AUTOSAR XML (schema 4-0-3)
package /AUTOSAR_Dcm/ImplementationDataTypes
  65 x impl type:
    Dcm_CertAuthorizationInfoType: category=ARRAY
      element authorization: array-size=4, array-size-semantics=FIXED-SIZE, implementation-data-type=uint8
    DataArrayType_WDBI_Factory_SerialNumber_0x12A3: category=ARRAY
      element DataArrayType: array-size=15, array-size-semantics=FIXED-SIZE, implementation-data-type=uint8
    Dcm_OpStatusType: category=VALUE, base-type=uint8, compu {0x00=DCM_INITIAL, 0x01=DCM_PENDING, 0x02=DCM_CANCEL, 0x03=DCM_FORCE_RCRRP_OK}, range raw 0x00..0x03
    RequestDataArray: category=ARRAY
      element RequestDataArray: array-size=255, array-size-semantics=FIXED-SIZE, implementation-data-type=uint8
    DataArrayType_ECUSupplierCodeDataIdentifier_0xF1A1: category=ARRAY
      element DataArrayType: array-size=4, array-size-semantics=FIXED-SIZE, implementation-data-type=uint8
    StartDataOutType_RID_B19Ch_HSMConfigurationLockEnable_B19Ch_StartRoutineOutSignal_ErrorCode: category=VALUE, base-type=uint16, range raw 0..65535
    DataArrayType_VehicleManufacturerECUHardwareNumberDataIdentifier_0xF191: category=ARRAY
      element DataArrayType: array-size=4, array-size-semantics=FIXED-SIZE, implementation-data-type=uint8
    DataArrayType_SystemName_0xF197: category=ARRAY
      element DataArrayType: array-size=4, array-size-semantics=FIXED-SIZE, implementation-data-type=uint8
    DataArrayType_ECUSoftwareInternalVersion_0xF189: category=ARRAY
      element DataArrayType: array-size=7, array-size-semantics=FIXED-SIZE, implementation-data-type=uint8
    SeedArrayType_L1: category=ARRAY
      element SeedArrayType: array-size=4, array-size-semantics=FIXED-SIZE, implementation-data-type=uint8
    Dcm_ConfirmationStatusType: category=VALUE, base-type=uint8, compu {0x00=DCM_RES_POS_OK, 0x01=DCM_RES_POS_NOT_OK, 0x02=DCM_RES_NEG_OK, 0x03=DCM_RES_NEG_NOT_OK}, range raw 0x00..0x03
    StartDataOutType_RID_0300h_OTAReady_Out_RoutineStatus: category=VALUE, base-type=uint8, range raw 0..255
    KeyArrayType_L9: category=ARRAY
      element KeyArrayType: array-size=8, array-size-semantics=FIXED-SIZE, implementation-data-type=uint8
    DataArrayType_ECUSoftwareUNIT1VersionDataIdentifier_0xF1B1: category=ARRAY
      element DataArrayType: array-size=4, array-size-semantics=FIXED-SIZE, implementation-data-type=uint8
    DataArrayType_SystemSupplierECUHardwareVersionNumberDataIdentifier_0xF193: category=ARRAY
      element DataArrayType: array-size=4, array-size-semantics=FIXED-SIZE, implementation-data-type=uint8
    DataArrayType_WDBI_ManufacturingDate_0x12A4: category=ARRAY
      element DataArrayType: array-size=4, array-size-semantics=FIXED-SIZE, implementation-data-type=uint8
    StartDataOutType_RID_B19Ch_HSMConfigurationLockEnable_B19Ch_StartRoutineOutSignal_State: category=VALUE, base-type=uint8, range raw 0..255
    StartDataOutType_RID_B199h_HSMSecureBootEnable_B199h_StartRoutineOutSignal_ErrorCode: category=VALUE, base-type=uint16, range raw 0..65535
    DataArrayType_InputOutputRecordLocalIdentifier_0xBE02: category=ARRAY
      element DataArrayType: array-size=14, array-size-semantics=FIXED-SIZE, implementation-data-type=uint8
    Dcm_ProgConditionsType: category=STRUCTURE
      8 x element, all with category=TYPE_REFERENCE:
        TesterSourceAddr: implementation-data-type=uint16
        ProtocolId: implementation-data-type=uint8
        Sid: implementation-data-type=uint8
        SubFncId: implementation-data-type=uint8
        ReprogramingRequest: implementation-data-type=boolean
        ApplUpdated: implementation-data-type=boolean
        ResponseRequired: implementation-data-type=boolean
        SecLvInfo: implementation-data-type=uint8
    Dcm_CertExpirationDateInfoType: category=ARRAY
      element expirationDate: array-size=3, array-size-semantics=FIXED-SIZE, implementation-data-type=uint8
    Dcm_PresentDateType: category=VALUE, base-type=uint8, range raw 0..255
    DataArrayType_InputOutputRecordLocalIdentifier_0xBE03: category=ARRAY
      element DataArrayType: array-size=6, array-size-semantics=FIXED-SIZE, implementation-data-type=uint8
    Dcm_StatusType: category=VALUE, base-type=uint8, compu {0x00=DCM_E_OK, 0x08=DCM_E_REQUEST_NOT_ACCEPTED, 0x05=DCM_E_PROTOCOL_NOT_ALLOWED, 0x06=DCM_E_ROE_NOT_ACCEPTED, 0x07=DCM_E_PERIODICID_NOT_ACCEPTED, 0x11=DCM_E_COMPARE_KEY_FAILED}, range raw 0x00..0x11
    StartDataOutType_RID_B19Ch_HSMConfigurationLockEnable_B19Ch_StartRoutineOutSignal_ReturnType: category=VALUE, base-type=uint8, range raw 0..255
    StartDataOutType_RID_B19Bh_HSMSecureDebugEnable_B19Bh_StartRoutineOutSignal_ErrorCode: category=VALUE, base-type=uint16, range raw 0..65535
    DataArrayType_PlatformHardwareVersion_0xF17D: category=ARRAY
      element DataArrayType: array-size=11, array-size-semantics=FIXED-SIZE, implementation-data-type=uint8
    Dcm_MsgItemType: category=VALUE, base-type=uint8, range raw 0..255
    Dcm_IdContextType: category=VALUE, base-type=uint8, range raw 0..255
    StartFlexibleInArrayDataType_RID_B19Eh_HSMResponseData_B19Eh_StartRoutineInSignal_Data: category=ARRAY
      element StartFlexibleInArrayDataType: array-size=16, array-size-semantics=FIXED-SIZE, implementation-data-type=uint8
    DataArrayType_ECUSerialNumberDataIdentifier_0xF18C: category=ARRAY
      element DataArrayType: array-size=15, array-size-semantics=FIXED-SIZE, implementation-data-type=uint8
    DcmDspDidRangeArrayType_DIDs_0100h_0110h: category=ARRAY
      element DcmDspDidRangeArrayType: array-size=30, array-size-semantics=FIXED-SIZE, implementation-data-type=uint8
    DataArrayType_ECUSoftwareUNITnumberDataIdentifier_0xF1B0: category=ARRAY
      element DataArrayType: array-size=1, array-size-semantics=FIXED-SIZE, implementation-data-type=uint8
    DataArrayType_ECUSoftwareUnit1IVDDataIdentifier_0xF1C1: category=ARRAY
      element DataArrayType: array-size=32, array-size-semantics=FIXED-SIZE, implementation-data-type=uint8
    DataArrayType_CANDataBaseVersionNumberDataIdentifier_0xF100: category=ARRAY
      element DataArrayType: array-size=4, array-size-semantics=FIXED-SIZE, implementation-data-type=uint8
    Dcm_CertInfoType: category=STRUCTURE
      element authorization: implementation-data-type=Dcm_CertAuthorizationInfoType
      element expirationDate: implementation-data-type=Dcm_CertExpirationDateInfoType
    Dcm_ReturnReadMemoryType: category=VALUE, base-type=uint8, compu {0x02=DCM_READ_FAILED, 0x03=DCM_READ_FORCE_RCRRP, 0x00=DCM_READ_OK, 0x01=DCM_READ_PENDING}, range raw 0x00..0x03
    StartFlexibleOutArrayDataType_RID_B19Dh_HSMChallengeRequest_B19Dh_StartRoutineOutSignal_Data: category=ARRAY
      element StartFlexibleOutArrayDataType: array-size=16, array-size-semantics=FIXED-SIZE, implementation-data-type=uint8
    DTRStatusType: category=VALUE, base-type=uint8, range raw 0..255
    Dcm_MsgLenType: category=VALUE, base-type=uint32, range raw 0..4294967295
    StartDataOutType_RID_B19Bh_HSMSecureDebugEnable_B19Bh_StartRoutineOutSignal_State: category=VALUE, base-type=uint8, range raw 0..255
    SeedArrayType_L9: category=ARRAY
      element SeedArrayType: array-size=8, array-size-semantics=FIXED-SIZE, implementation-data-type=uint8
    DataArrayType_PlatformVersion_0xF17F: category=ARRAY
      element DataArrayType: array-size=11, array-size-semantics=FIXED-SIZE, implementation-data-type=uint8
    KeyArrayType_L1: category=ARRAY
      element KeyArrayType: array-size=4, array-size-semantics=FIXED-SIZE, implementation-data-type=uint8
    StartFlexibleOutArrayDataType_RID_B194h_HSMConfigLockSecureDebug_B194h_StartRoutineOutSignal: category=ARRAY
      element StartFlexibleOutArrayDataType: array-size=2, array-size-semantics=FIXED-SIZE, implementation-data-type=uint8
    Dcm_SesCtrlType: category=VALUE, base-type=uint8, compu {0x01=DCM_DEFAULT_SESSION, 0x02=DCM_PROGRAMMING_SESSION, 0x03=DCM_EXTENDED_DIAGNOSTIC_SESSION, 0x04=DCM_SAFETY_SYSTEM_DIAGNOSTIC_SESSION, 0x10=DCM_EXTENDED_DIAGNOSTIC_MODE_10H, 0x05=DCM_ECU_PROGRAMMING_MODE_05H, 0x50=DCM_QUIESCENT_CURRENT_DIAGNOSTIC_MODE_START, 0x51=DCM_SLEEP_MODE_START_REQUEST, 0xFF=DCM_ALL_SESSION_LEVEL}, range raw 0x01..0xFF
    DataArrayType_ReadECUIdentificationLocalRXSWINDataIdentifier_0xF1EF: category=ARRAY
      element DataArrayType: array-size=40, array-size-semantics=FIXED-SIZE, implementation-data-type=uint8
    Dcm_ReturnWriteMemoryType: category=VALUE, base-type=uint8, compu {0x02=DCM_WRITE_FAILED, 0x03=DCM_WRITE_FORCE_RCRRP, 0x00=DCM_WRITE_OK, 0x01=DCM_WRITE_PENDING}, range raw 0x00..0x03
    Dcm_ProtocolType:
      category=VALUE
      base-type=uint8
      compu {0x00=DCM_OBD_ON_CAN, 0x01=DCM_OBD_ON_FLEXRAY, 0x02=DCM_OBD_ON_IP, 0x03=DCM_UDS_ON_CAN, 0x04=DCM_UDS_ON_FLEXRAY, 0x05=DCM_UDS_ON_IP, 0x06=DCM_ROE_ON_CAN, 0x07=DCM_ROE_ON_FLEXRAY, 0x08=DCM_ROE_ON_IP, 0x09=DCM_PERIODICTRANS_ON_CAN, 0x0A=DCM_PERIODICTRANS_ON_FLEXRAY, 0x0B=DCM_PERIODICTRANS_ON_IP, 0x0C=DCM_NO_ACTIVE_PROTOCOL, 0xF0=DCM_SUPPLIER_1, 0xF1=DCM_SUPPLIER_2, 0xF2=DCM_SUPPLIER_3, 0xF3=DCM_SUPPLIER_4, 0xF4=DCM_SUPPLIER_5, 0xF5=DCM_SUPPLIER_6, 0xF6=DCM_SUPPLIER_7, 0xF7=DCM_SUPPLIER_8, 0xF8=DCM_SUPPLIER_9, 0xF9=DCM_SUPPLIER_10, 0xFA=DCM_SUPPLIER_11, 0xFB=DCM_SUPPLIER_12, 0xFC=DCM_SUPPLIER_13, 0xFD=DCM_SUPPLIER_14, 0xFE=DCM_SUPPLIER_15}
      range raw 0x00..0xFE
    StartDataOutType_RID_B19Bh_HSMSecureDebugEnable_B19Bh_StartRoutineOutSignal_ReturnType: category=VALUE, base-type=uint8, range raw 0..255
    Dcm_RoeStateType: category=VALUE, base-type=uint8, compu {0x00=DCM_ROE_ACTIVE, 0x01=DCM_ROE_UNACTIVE}, range raw 0x00..0x01
    DataArrayType_VehicleManufacturerSparePartNumberDataIdentifier_0xF187: category=ARRAY
      element DataArrayType: array-size=10, array-size-semantics=FIXED-SIZE, implementation-data-type=uint8
    DataArrayType_NonSleepCollectedEachEcuDataIdentifier_0xED90: category=ARRAY
      element DataArrayType: array-size=15, array-size-semantics=FIXED-SIZE, implementation-data-type=uint8
    StartDataOutType_RID_B199h_HSMSecureBootEnable_B199h_StartRoutineOutSignal_ReturnType: category=VALUE, base-type=uint8, range raw 0..255
    DataArrayType_ECUManufacturingDateDataIdentifier_0xF18B: category=ARRAY
      element DataArrayType: array-size=4, array-size-semantics=FIXED-SIZE, implementation-data-type=uint8
    DataArrayType_UserOptionRecordLocalIdentifier_0xBE01: category=ARRAY
      element DataArrayType: array-size=8, array-size-semantics=FIXED-SIZE, implementation-data-type=uint8
    StartDataOutType_RID_B19Ah_HSMFTDDisable_B19Ah_StartRoutineOutSignal_ErrorCode: category=VALUE, base-type=uint16, range raw 0..65535
    StartDataOutType_RID_B19Ah_HSMFTDDisable_B19Ah_StartRoutineOutSignal_ReturnType: category=VALUE, base-type=uint8, range raw 0..255
    Dcm_SecLevelType: category=VALUE, base-type=uint8, compu {0x00=DCM_SEC_LEV_LOCKED, 0x01=DCM_SEC_LEV_L1, 0x09=DCM_SEC_LEV_L9, 0x21=DCM_SEC_LEV_L21, 0xFF=DCM_SEC_LEV_ALL}, range raw 0x00..0xFF
    Dcm_NegativeResponseCodeType:
      category=VALUE
      base-type=uint8
      compu {0x00=DCM_E_POSITIVERESPONSE, 0x10=DCM_E_GENERALREJECT, 0x11=DCM_E_SERVICENOTSUPPORTED, 0x12=DCM_E_SUBFUNCTIONNOTSUPPORTED, 0x13=DCM_E_INCORRECTMESSAGELENGTHORINVALIDFORMAT, 0x14=DCM_E_RESPONSETOOLONG, 0x21=DCM_E_BUSYREPEATREQUEST, 0x22=DCM_E_CONDITIONSNOTCORRECT, 0x24=DCM_E_REQUESTSEQUENCEERROR, 0x25=DCM_E_NORESPONSEFROMSUBNETCOMPONENT, 0x26=DCM_E_FAILUREPREVENTSEXECUTIONOFREQUESTEDACTION, 0x31=DCM_E_REQUESTOUTOFRANGE, 0x33=DCM_E_SECURITYACCESSDENIED, 0x35=DCM_E_INVALIDKEY, 0x36=DCM_E_EXCEEDNUMBEROFATTEMPTS, 0x37=DCM_E_REQUIREDTIMEDELAYNOTEXPIRED, 0x70=DCM_E_UPLOADDOWNLOADNOTACCEPTED, 0x71=DCM_E_TRANSFERDATASUSPENDED, 0x72=DCM_E_GENERALPROGRAMMINGFAILURE, 0x73=DCM_E_WRONGBLOCKSEQUENCECOUNTER, 0x7E=DCM_E_SUBFUNCTIONNOTSUPPORTEDINACTIVESESSION, 0x7F=DCM_E_SERVICENOTSUPPORTEDINACTIVESESSION, 0x81=DCM_E_RPMTOOHIGH, 0x82=DCM_E_RPMTOOLOW, 0x83=DCM_E_ENGINEISRUNNING, 0x84=DCM_E_ENGINEISNOTRUNNING, 0x85=DCM_E_ENGINERUNTIMETOOLOW, 0x86=DCM_E_TEMPERATURETOOHIGH, 0x87=DCM_E_TEMPERATURETOOLOW, 0x88=DCM_E_VEHICLESPEEDTOOHIGH, 0x89=DCM_E_VEHICLESPEEDTOOLOW, 0x8A=DCM_E_THROTTLE_PEDALTOOHIGH, 0x8B=DCM_E_THROTTLE_PEDALTOOLOW, 0x8C=DCM_E_TRANSMISSIONRANGENOTINNEUTRAL, 0x8D=DCM_E_TRANSMISSIONRANGENOTINGEAR, 0x8F=DCM_E_BRAKESWITCH_NOTCLOSED, 0x90=DCM_E_SHIFTERLEVERNOTINPARK, 0x91=DCM_E_TORQUECONVERTERCLUTCHLOCKED, 0x92=DCM_E_VOLTAGETOOHIGH, 0x93=DCM_E_VOLTAGETOOLOW, 0xF0=DCM_E_CRLINTEGRITYCHECKFAILED, 0xF1=DCM_E_CRLEXPIRED, 0xF2=DCM_E_CERTVERIFICATIONFAILED, 0xF3=DCM_E_VMSCNC_3, 0xF4=DCM_E_VMSCNC_4, 0xF5=DCM_E_VMSCNC_5, 0xF6=DCM_E_VMSCNC_6, 0xF7=DCM_E_VMSCNC_7, 0xF8=DCM_E_VMSCNC_8, 0xF9=DCM_E_VMSCNC_9, 0xFA=DCM_E_VMSCNC_A, 0xFB=DCM_E_VMSCNC_B, 0xFC=DCM_E_VMSCNC_C, 0xFD=DCM_E_VMSCNC_D, 0xFE=DCM_E_VMSCNC_E}
      range raw 0x00..0xFF
    Dcm_CommunicationModeType:
      category=VALUE
      base-type=uint8
      compu {0x00=DCM_ENABLE_RX_TX_NORM, 0x01=DCM_ENABLE_RX_DISABLE_TX_NORM, 0x02=DCM_DISABLE_RX_ENABLE_TX_NORM, 0x03=DCM_DISABLE_RX_TX_NORMAL, 0x04=DCM_ENABLE_RX_TX_NM, 0x05=DCM_ENABLE_RX_DISABLE_TX_NM, 0x06=DCM_DISABLE_RX_ENABLE_TX_NM, 0x07=DCM_DISABLE_RX_TX_NM, 0x08=DCM_ENABLE_RX_TX_NORM_NM, 0x09=DCM_ENABLE_RX_DISABLE_TX_NORM_NM, 0x0A=DCM_DISABLE_RX_ENABLE_TX_NORM_NM, 0x0B=DCM_DISABLE_RX_TX_NORM_NM, 0x03=DCM_DISABLE_RX_TX_NORM}
      range raw 0x00..0x0B
    StartDataOutType_RID_B199h_HSMSecureBootEnable_B199h_StartRoutineOutSignal_State: category=VALUE, base-type=uint8, range raw 0..255
    DataArrayType_ChargingECUSoftwareVersionMobase_0xF101: category=ARRAY
      element DataArrayType: array-size=6, array-size-semantics=FIXED-SIZE, implementation-data-type=uint8
    StartDataOutType_RID_B19Ah_HSMFTDDisable_B19Ah_StartRoutineOutSignal_State: category=VALUE, base-type=uint8, range raw 0..255
    Dcm_EcuStartModeType: category=VALUE, base-type=uint8, compu {0x00=DCM_COLD_START, 0x01=DCM_WARM_START}, range raw 0x00..0x01
package /AUTOSAR_Dcm/ClientServerInterfaces
  37 x client server interface, all with is-service=true:
    RoutineServices_RID_B19Bh_HSMSecureDebugEnable
      operation Start: possible-error=[RoutineServices_RID_B19Bh_HSMSecureDebugEnable/DCM_E_FORCE_RCRRP, RoutineServices_RID_B19Bh_HSMSecureDebugEnable/DCM_E_PENDING, RoutineServices_RID_B19Bh_HSMSecureDebugEnable/E_NOT_OK]
        6 x arg:
          OpStatus: type=Dcm_OpStatusType, direction=IN
          DataOut_B19Bh_StartRoutineOutSignal_ReturnType: type=StartDataOutType_RID_B19Bh_HSMSecureDebugEnable_B19Bh_StartRoutineOutSignal_ReturnType, direction=OUT
          DataOut_B19Bh_StartRoutineOutSignal_State: type=StartDataOutType_RID_B19Bh_HSMSecureDebugEnable_B19Bh_StartRoutineOutSignal_State, direction=OUT
          DataOut_B19Bh_StartRoutineOutSignal_ErrorCode: type=StartDataOutType_RID_B19Bh_HSMSecureDebugEnable_B19Bh_StartRoutineOutSignal_ErrorCode, direction=OUT
          currentDataLength: type=uint16, direction=INOUT
          ErrorCode: type=Dcm_NegativeResponseCodeType, direction=OUT
      error DCM_E_FORCE_RCRRP: error-code=12
      error DCM_E_PENDING: error-code=10
      error E_NOT_OK: error-code=1
    DataServices_VehicleManufacturerSparePartNumberDataIdentifier_0xF187
      operation ReadData: possible-error=DataServices_VehicleManufacturerSparePartNumberDataIdentifier_0xF187/E_NOT_OK
        arg Data: type=DataArrayType_VehicleManufacturerSparePartNumberDataIdentifier_0xF187, direction=OUT
      operation ConditionCheckRead: possible-error=DataServices_VehicleManufacturerSparePartNumberDataIdentifier_0xF187/E_NOT_OK
        arg ErrorCode: type=Dcm_NegativeResponseCodeType, direction=OUT
      error E_NOT_OK: error-code=1
      error DCM_E_PENDING: error-code=10
    DataServices_CANDataBaseVersionNumberDataIdentifier_0xF100
      operation ReadData: possible-error=DataServices_CANDataBaseVersionNumberDataIdentifier_0xF100/E_NOT_OK
        arg Data: type=DataArrayType_CANDataBaseVersionNumberDataIdentifier_0xF100, direction=OUT
      operation ConditionCheckRead: possible-error=DataServices_CANDataBaseVersionNumberDataIdentifier_0xF100/E_NOT_OK
        arg ErrorCode: type=Dcm_NegativeResponseCodeType, direction=OUT
      error DCM_E_PENDING: error-code=10
      error E_NOT_OK: error-code=1
    DataServices_NonSleepCollectedEachEcuDataIdentifier_0xED90
      operation ReadData: possible-error=DataServices_NonSleepCollectedEachEcuDataIdentifier_0xED90/E_NOT_OK
        arg Data: type=DataArrayType_NonSleepCollectedEachEcuDataIdentifier_0xED90, direction=OUT
      operation ConditionCheckRead: possible-error=DataServices_NonSleepCollectedEachEcuDataIdentifier_0xED90/E_NOT_OK
        arg ErrorCode: type=Dcm_NegativeResponseCodeType, direction=OUT
      error E_NOT_OK: error-code=1
      error DCM_E_PENDING: error-code=10
    DataServices_PlatformHardwareVersion_0xF17D
      operation ReadData: possible-error=DataServices_PlatformHardwareVersion_0xF17D/E_NOT_OK
        arg Data: type=DataArrayType_PlatformHardwareVersion_0xF17D, direction=OUT
      operation ConditionCheckRead: possible-error=DataServices_PlatformHardwareVersion_0xF17D/E_NOT_OK
        arg ErrorCode: type=Dcm_NegativeResponseCodeType, direction=OUT
      error DCM_E_PENDING: error-code=10
      error E_NOT_OK: error-code=1
    DataServices_ECUSerialNumberDataIdentifier_0xF18C
      operation ConditionCheckRead: possible-error=DataServices_ECUSerialNumberDataIdentifier_0xF18C/E_NOT_OK
        arg ErrorCode: type=Dcm_NegativeResponseCodeType, direction=OUT
      operation ReadData: possible-error=DataServices_ECUSerialNumberDataIdentifier_0xF18C/E_NOT_OK
        arg Data: type=DataArrayType_ECUSerialNumberDataIdentifier_0xF18C, direction=OUT
      error E_NOT_OK: error-code=1
      error DCM_E_PENDING: error-code=10
    RoutineServices_RID_B19Eh_HSMResponseData
      operation Start: possible-error=[RoutineServices_RID_B19Eh_HSMResponseData/DCM_E_PENDING, RoutineServices_RID_B19Eh_HSMResponseData/E_NOT_OK, RoutineServices_RID_B19Eh_HSMResponseData/DCM_E_FORCE_RCRRP]
        4 x arg:
          DataIn_B19Eh_StartRoutineInSignal_Data: type=StartFlexibleInArrayDataType_RID_B19Eh_HSMResponseData_B19Eh_StartRoutineInSignal_Data, direction=IN
          OpStatus: type=Dcm_OpStatusType, direction=IN
          currentDataLength: type=uint16, direction=INOUT
          ErrorCode: type=Dcm_NegativeResponseCodeType, direction=OUT
      error DCM_E_FORCE_RCRRP: error-code=12
      error DCM_E_PENDING: error-code=10
      error E_NOT_OK: error-code=1
    ServiceRequestNotification
      operation Confirmation: possible-error=ServiceRequestNotification/E_NOT_OK
        4 x arg, all with direction=IN:
          SID: type=uint8
          ReqType: type=uint8
          SourceAddress: type=uint16
          ConfirmationStatus: type=Dcm_ConfirmationStatusType
      operation Indication: possible-error=[ServiceRequestNotification/E_NOT_OK, E_REQUEST_NOT_ACCEPTED]
        6 x arg:
          SID: type=uint8, direction=IN
          RequestData: type=RequestDataArray, direction=IN
          DataSize: type=uint16, direction=IN
          ReqType: type=uint8, direction=IN
          SourceAddress: type=uint16, direction=IN
          ErrorCode: type=Dcm_NegativeResponseCodeType, direction=OUT
      error E_REQUEST_NOT_ACCEPTED: error-code=8
      error E_NOT_OK: error-code=1
    DataServices_ReadECUIdentificationLocalRXSWINDataIdentifier_0xF1EF
      operation ReadData: possible-error=[DataServices_ReadECUIdentificationLocalRXSWINDataIdentifier_0xF1EF/DCM_E_PENDING, DataServices_ReadECUIdentificationLocalRXSWINDataIdentifier_0xF1EF/E_NOT_OK]
        arg OpStatus: type=Dcm_OpStatusType, direction=IN
        arg Data: type=DataArrayType_ReadECUIdentificationLocalRXSWINDataIdentifier_0xF1EF, direction=OUT
      operation ConditionCheckRead: possible-error=[DataServices_ReadECUIdentificationLocalRXSWINDataIdentifier_0xF1EF/DCM_E_PENDING, DataServices_ReadECUIdentificationLocalRXSWINDataIdentifier_0xF1EF/E_NOT_OK]
        arg OpStatus: type=Dcm_OpStatusType, direction=IN
        arg ErrorCode: type=Dcm_NegativeResponseCodeType, direction=OUT
      error DCM_E_PENDING: error-code=10
      error E_NOT_OK: error-code=1
    CallbackDCMRequestServices
      operation StopProtocol: possible-error=CallbackDCMRequestServices/E_NOT_OK
        arg ProtocolID: type=Dcm_ProtocolType, direction=IN
      operation StartProtocol: possible-error=[CallbackDCMRequestServices/E_NOT_OK, E_PROTOCOL_NOT_ALLOWED]
        arg ProtocolID: type=Dcm_ProtocolType, direction=IN
      error E_NOT_OK: error-code=1
      error E_PROTOCOL_NOT_ALLOWED: error-code=5
    DataServices_ECUSoftwareUNITnumberDataIdentifier_0xF1B0
      operation ReadData: possible-error=DataServices_ECUSoftwareUNITnumberDataIdentifier_0xF1B0/E_NOT_OK
        arg Data: type=DataArrayType_ECUSoftwareUNITnumberDataIdentifier_0xF1B0, direction=OUT
      operation ConditionCheckRead: possible-error=DataServices_ECUSoftwareUNITnumberDataIdentifier_0xF1B0/E_NOT_OK
        arg ErrorCode: type=Dcm_NegativeResponseCodeType, direction=OUT
      error DCM_E_PENDING: error-code=10
      error E_NOT_OK: error-code=1
    RoutineServices_RID_B19Dh_HSMChallengeRequest
      operation Start: possible-error=[RoutineServices_RID_B19Dh_HSMChallengeRequest/DCM_E_PENDING, RoutineServices_RID_B19Dh_HSMChallengeRequest/E_NOT_OK, RoutineServices_RID_B19Dh_HSMChallengeRequest/DCM_E_FORCE_RCRRP]
        4 x arg:
          OpStatus: type=Dcm_OpStatusType, direction=IN
          DataOut_B19Dh_StartRoutineOutSignal_Data: type=StartFlexibleOutArrayDataType_RID_B19Dh_HSMChallengeRequest_B19Dh_StartRoutineOutSignal_Data, direction=OUT
          currentDataLength: type=uint16, direction=INOUT
          ErrorCode: type=Dcm_NegativeResponseCodeType, direction=OUT
      error DCM_E_PENDING: error-code=10
      error E_NOT_OK: error-code=1
      error DCM_E_FORCE_RCRRP: error-code=12
    DataServices_InputOutputRecordLocalIdentifier_0xBE03
      operation ConditionCheckRead: possible-error=DataServices_InputOutputRecordLocalIdentifier_0xBE03/E_NOT_OK
        arg ErrorCode: type=Dcm_NegativeResponseCodeType, direction=OUT
      operation ReadData: possible-error=DataServices_InputOutputRecordLocalIdentifier_0xBE03/E_NOT_OK
        arg Data: type=DataArrayType_InputOutputRecordLocalIdentifier_0xBE03, direction=OUT
      error E_NOT_OK: error-code=1
      error DCM_E_PENDING: error-code=10
    CallbackDCMPresentDate
      operation GetPresentDate: possible-error=CallbackDCMPresentDate/E_NOT_OK
        arg Date: type=Dcm_PresentDateType, direction=OUT
      error E_NOT_OK: error-code=1
    DCMServices
      5 x operation, all with possible-error=DCMServices/E_NOT_OK:
        ResetToDefaultSession
        GetActiveProtocol
          arg ActiveProtocol: type=Dcm_ProtocolType, direction=OUT
        GetSecurityLevel
          arg SecLevel: type=Dcm_SecLevelType, direction=OUT
        GetSesCtrlType
          arg SesCtrlType: type=Dcm_SesCtrlType, direction=OUT
        GetCertificationInfo
          arg CertInfo: type=Dcm_CertInfoType, direction=OUT
      error E_NOT_OK: error-code=1
    RoutineServices_RID_B19Ch_HSMConfigurationLockEnable
      operation Start: possible-error=[RoutineServices_RID_B19Ch_HSMConfigurationLockEnable/E_NOT_OK, RoutineServices_RID_B19Ch_HSMConfigurationLockEnable/DCM_E_PENDING, RoutineServices_RID_B19Ch_HSMConfigurationLockEnable/DCM_E_FORCE_RCRRP]
        6 x arg:
          OpStatus: type=Dcm_OpStatusType, direction=IN
          DataOut_B19Ch_StartRoutineOutSignal_ReturnType: type=StartDataOutType_RID_B19Ch_HSMConfigurationLockEnable_B19Ch_StartRoutineOutSignal_ReturnType, direction=OUT
          DataOut_B19Ch_StartRoutineOutSignal_State: type=StartDataOutType_RID_B19Ch_HSMConfigurationLockEnable_B19Ch_StartRoutineOutSignal_State, direction=OUT
          DataOut_B19Ch_StartRoutineOutSignal_ErrorCode: type=StartDataOutType_RID_B19Ch_HSMConfigurationLockEnable_B19Ch_StartRoutineOutSignal_ErrorCode, direction=OUT
          currentDataLength: type=uint16, direction=INOUT
          ErrorCode: type=Dcm_NegativeResponseCodeType, direction=OUT
      error DCM_E_FORCE_RCRRP: error-code=12
      error E_NOT_OK: error-code=1
      error DCM_E_PENDING: error-code=10
    SecurityAccess_L1
      operation CompareKey: possible-error=[SecurityAccess_L1/E_NOT_OK, SecurityAccess_L1/DCM_E_COMPARE_KEY_FAILED, SecurityAccess_L1/DCM_E_PENDING]
        arg Key: type=KeyArrayType_L1, direction=IN
        arg OpStatus: type=Dcm_OpStatusType, direction=IN
      operation GetSeed: possible-error=[SecurityAccess_L1/DCM_E_PENDING, SecurityAccess_L1/E_NOT_OK]
        arg OpStatus: type=Dcm_OpStatusType, direction=IN
        arg Seed: type=SeedArrayType_L1, direction=OUT
        arg ErrorCode: type=Dcm_NegativeResponseCodeType, direction=OUT
      error DCM_E_PENDING: error-code=10
      error DCM_E_COMPARE_KEY_FAILED: error-code=11
      error E_NOT_OK: error-code=1
    DataServices_PlatformVersion_0xF17F
      operation ConditionCheckRead: possible-error=DataServices_PlatformVersion_0xF17F/E_NOT_OK
        arg ErrorCode: type=Dcm_NegativeResponseCodeType, direction=OUT
      operation ReadData: possible-error=DataServices_PlatformVersion_0xF17F/E_NOT_OK
        arg Data: type=DataArrayType_PlatformVersion_0xF17F, direction=OUT
      error DCM_E_PENDING: error-code=10
      error E_NOT_OK: error-code=1
    RoutineServices_RID_B19Ah_HSMFTDDisable
      operation Start: possible-error=[RoutineServices_RID_B19Ah_HSMFTDDisable/DCM_E_FORCE_RCRRP, RoutineServices_RID_B19Ah_HSMFTDDisable/E_NOT_OK, RoutineServices_RID_B19Ah_HSMFTDDisable/DCM_E_PENDING]
        6 x arg:
          OpStatus: type=Dcm_OpStatusType, direction=IN
          DataOut_B19Ah_StartRoutineOutSignal_ReturnType: type=StartDataOutType_RID_B19Ah_HSMFTDDisable_B19Ah_StartRoutineOutSignal_ReturnType, direction=OUT
          DataOut_B19Ah_StartRoutineOutSignal_State: type=StartDataOutType_RID_B19Ah_HSMFTDDisable_B19Ah_StartRoutineOutSignal_State, direction=OUT
          DataOut_B19Ah_StartRoutineOutSignal_ErrorCode: type=StartDataOutType_RID_B19Ah_HSMFTDDisable_B19Ah_StartRoutineOutSignal_ErrorCode, direction=OUT
          currentDataLength: type=uint16, direction=INOUT
          ErrorCode: type=Dcm_NegativeResponseCodeType, direction=OUT
      error E_NOT_OK: error-code=1
      error DCM_E_PENDING: error-code=10
      error DCM_E_FORCE_RCRRP: error-code=12
    DataServices_ECUSoftwareInternalVersion_0xF189
      operation ConditionCheckRead: possible-error=DataServices_ECUSoftwareInternalVersion_0xF189/E_NOT_OK
        arg ErrorCode: type=Dcm_NegativeResponseCodeType, direction=OUT
      operation ReadData: possible-error=DataServices_ECUSoftwareInternalVersion_0xF189/E_NOT_OK
        arg Data: type=DataArrayType_ECUSoftwareInternalVersion_0xF189, direction=OUT
      error DCM_E_PENDING: error-code=10
      error E_NOT_OK: error-code=1
    DataServices_VehicleManufacturerECUHardwareNumberDataIdentifier_0xF191
      operation ConditionCheckRead: possible-error=DataServices_VehicleManufacturerECUHardwareNumberDataIdentifier_0xF191/E_NOT_OK
        arg ErrorCode: type=Dcm_NegativeResponseCodeType, direction=OUT
      operation ReadData: possible-error=DataServices_VehicleManufacturerECUHardwareNumberDataIdentifier_0xF191/E_NOT_OK
        arg Data: type=DataArrayType_VehicleManufacturerECUHardwareNumberDataIdentifier_0xF191, direction=OUT
      error DCM_E_PENDING: error-code=10
      error E_NOT_OK: error-code=1
    DataServices_UserOptionRecordLocalIdentifier_0xBE01
      operation ConditionCheckRead: possible-error=DataServices_UserOptionRecordLocalIdentifier_0xBE01/E_NOT_OK
        arg ErrorCode: type=Dcm_NegativeResponseCodeType, direction=OUT
      operation ReadData: possible-error=DataServices_UserOptionRecordLocalIdentifier_0xBE01/E_NOT_OK
        arg Data: type=DataArrayType_UserOptionRecordLocalIdentifier_0xBE01, direction=OUT
      error DCM_E_PENDING: error-code=10
      error E_NOT_OK: error-code=1
    DataServices_ECUSupplierCodeDataIdentifier_0xF1A1
      operation ConditionCheckRead: possible-error=DataServices_ECUSupplierCodeDataIdentifier_0xF1A1/E_NOT_OK
        arg ErrorCode: type=Dcm_NegativeResponseCodeType, direction=OUT
      operation ReadData: possible-error=DataServices_ECUSupplierCodeDataIdentifier_0xF1A1/E_NOT_OK
        arg Data: type=DataArrayType_ECUSupplierCodeDataIdentifier_0xF1A1, direction=OUT
      error DCM_E_PENDING: error-code=10
      error E_NOT_OK: error-code=1
    DataServices_InputOutputRecordLocalIdentifier_0xBE02
      operation ConditionCheckRead: possible-error=DataServices_InputOutputRecordLocalIdentifier_0xBE02/E_NOT_OK
        arg ErrorCode: type=Dcm_NegativeResponseCodeType, direction=OUT
      operation ReadData: possible-error=DataServices_InputOutputRecordLocalIdentifier_0xBE02/E_NOT_OK
        arg Data: type=DataArrayType_InputOutputRecordLocalIdentifier_0xBE02, direction=OUT
      error E_NOT_OK: error-code=1
      error DCM_E_PENDING: error-code=10
    DataServices_ECUManufacturingDateDataIdentifier_0xF18B
      operation ReadData: possible-error=DataServices_ECUManufacturingDateDataIdentifier_0xF18B/E_NOT_OK
        arg Data: type=DataArrayType_ECUManufacturingDateDataIdentifier_0xF18B, direction=OUT
      operation ConditionCheckRead: possible-error=DataServices_ECUManufacturingDateDataIdentifier_0xF18B/E_NOT_OK
        arg ErrorCode: type=Dcm_NegativeResponseCodeType, direction=OUT
      error DCM_E_PENDING: error-code=10
      error E_NOT_OK: error-code=1
    DataServices_SystemSupplierECUHardwareVersionNumberDataIdentifier_0xF193
      operation ReadData: possible-error=DataServices_SystemSupplierECUHardwareVersionNumberDataIdentifier_0xF193/E_NOT_OK
        arg Data: type=DataArrayType_SystemSupplierECUHardwareVersionNumberDataIdentifier_0xF193, direction=OUT
      operation ConditionCheckRead: possible-error=DataServices_SystemSupplierECUHardwareVersionNumberDataIdentifier_0xF193/E_NOT_OK
        arg ErrorCode: type=Dcm_NegativeResponseCodeType, direction=OUT
      error DCM_E_PENDING: error-code=10
      error E_NOT_OK: error-code=1
    DataServices_ECUSoftwareUnit1IVDDataIdentifier_0xF1C1
      operation ConditionCheckRead: possible-error=[DataServices_ECUSoftwareUnit1IVDDataIdentifier_0xF1C1/DCM_E_PENDING, DataServices_ECUSoftwareUnit1IVDDataIdentifier_0xF1C1/E_NOT_OK]
        arg OpStatus: type=Dcm_OpStatusType, direction=IN
        arg ErrorCode: type=Dcm_NegativeResponseCodeType, direction=OUT
      operation ReadData: possible-error=[DataServices_ECUSoftwareUnit1IVDDataIdentifier_0xF1C1/DCM_E_PENDING, DataServices_ECUSoftwareUnit1IVDDataIdentifier_0xF1C1/E_NOT_OK]
        arg OpStatus: type=Dcm_OpStatusType, direction=IN
        arg Data: type=DataArrayType_ECUSoftwareUnit1IVDDataIdentifier_0xF1C1, direction=OUT
      error E_NOT_OK: error-code=1
      error DCM_E_PENDING: error-code=10
    DataServices_WDBI_ManufacturingDate_0x12A4
      operation WriteData: possible-error=DataServices_WDBI_ManufacturingDate_0x12A4/E_NOT_OK
        arg Data: type=DataArrayType_WDBI_ManufacturingDate_0x12A4, direction=IN
        arg ErrorCode: type=Dcm_NegativeResponseCodeType, direction=OUT
      error E_NOT_OK: error-code=1
      error DCM_E_PENDING: error-code=10
    DataServices_ECUSoftwareUNIT1VersionDataIdentifier_0xF1B1
      operation ReadData: possible-error=DataServices_ECUSoftwareUNIT1VersionDataIdentifier_0xF1B1/E_NOT_OK
        arg Data: type=DataArrayType_ECUSoftwareUNIT1VersionDataIdentifier_0xF1B1, direction=OUT
      operation ConditionCheckRead: possible-error=DataServices_ECUSoftwareUNIT1VersionDataIdentifier_0xF1B1/E_NOT_OK
        arg ErrorCode: type=Dcm_NegativeResponseCodeType, direction=OUT
      error DCM_E_PENDING: error-code=10
      error E_NOT_OK: error-code=1
    RoutineServices_RID_0300h_OTAReady
      operation Start: possible-error=[RoutineServices_RID_0300h_OTAReady/DCM_E_FORCE_RCRRP, RoutineServices_RID_0300h_OTAReady/E_NOT_OK, RoutineServices_RID_0300h_OTAReady/DCM_E_PENDING]
        arg OpStatus: type=Dcm_OpStatusType, direction=IN
        arg DataOut_Out_RoutineStatus: type=StartDataOutType_RID_0300h_OTAReady_Out_RoutineStatus, direction=OUT
        arg ErrorCode: type=Dcm_NegativeResponseCodeType, direction=OUT
      error DCM_E_PENDING: error-code=10
      error E_NOT_OK: error-code=1
      error DCM_E_FORCE_RCRRP: error-code=12
    DataServices_WDBI_Factory_SerialNumber_0x12A3
      operation WriteData: possible-error=DataServices_WDBI_Factory_SerialNumber_0x12A3/E_NOT_OK
        arg Data: type=DataArrayType_WDBI_Factory_SerialNumber_0x12A3, direction=IN
        arg ErrorCode: type=Dcm_NegativeResponseCodeType, direction=OUT
      error DCM_E_PENDING: error-code=10
      error E_NOT_OK: error-code=1
    DataServices_SystemName_0xF197
      operation ReadData: possible-error=DataServices_SystemName_0xF197/E_NOT_OK
        arg Data: type=DataArrayType_SystemName_0xF197, direction=OUT
      operation ConditionCheckRead: possible-error=DataServices_SystemName_0xF197/E_NOT_OK
        arg ErrorCode: type=Dcm_NegativeResponseCodeType, direction=OUT
      error E_NOT_OK: error-code=1
      error DCM_E_PENDING: error-code=10
    DataServices_ChargingECUSoftwareVersionMobase_0xF101
      operation ReadData: possible-error=DataServices_ChargingECUSoftwareVersionMobase_0xF101/E_NOT_OK
        arg Data: type=DataArrayType_ChargingECUSoftwareVersionMobase_0xF101, direction=OUT
      operation ConditionCheckRead: possible-error=DataServices_ChargingECUSoftwareVersionMobase_0xF101/E_NOT_OK
        arg ErrorCode: type=Dcm_NegativeResponseCodeType, direction=OUT
      error E_NOT_OK: error-code=1
      error DCM_E_PENDING: error-code=10
    RoutineServices_RID_B199h_HSMSecureBootEnable
      operation Start: possible-error=[RoutineServices_RID_B199h_HSMSecureBootEnable/DCM_E_PENDING, RoutineServices_RID_B199h_HSMSecureBootEnable/E_NOT_OK, RoutineServices_RID_B199h_HSMSecureBootEnable/DCM_E_FORCE_RCRRP]
        6 x arg:
          OpStatus: type=Dcm_OpStatusType, direction=IN
          DataOut_B199h_StartRoutineOutSignal_ReturnType: type=StartDataOutType_RID_B199h_HSMSecureBootEnable_B199h_StartRoutineOutSignal_ReturnType, direction=OUT
          DataOut_B199h_StartRoutineOutSignal_State: type=StartDataOutType_RID_B199h_HSMSecureBootEnable_B199h_StartRoutineOutSignal_State, direction=OUT
          DataOut_B199h_StartRoutineOutSignal_ErrorCode: type=StartDataOutType_RID_B199h_HSMSecureBootEnable_B199h_StartRoutineOutSignal_ErrorCode, direction=OUT
          currentDataLength: type=uint16, direction=INOUT
          ErrorCode: type=Dcm_NegativeResponseCodeType, direction=OUT
      error DCM_E_FORCE_RCRRP: error-code=12
      error DCM_E_PENDING: error-code=10
      error E_NOT_OK: error-code=1
    DataServices_DIDRange_DIDs_0100h_0110h
      operation ReadDidData: possible-error=[DataServices_DIDRange_DIDs_0100h_0110h/E_NOT_OK, DataServices_DIDRange_DIDs_0100h_0110h/DCM_E_PENDING]
        5 x arg:
          DID: type=uint16, direction=IN
          Data: type=DcmDspDidRangeArrayType_DIDs_0100h_0110h, direction=OUT
          OpStatus: type=Dcm_OpStatusType, direction=IN
          DataLength: type=uint16, direction=OUT
          ErrorCode: type=Dcm_NegativeResponseCodeType, direction=OUT
      operation WriteDidData: possible-error=[DataServices_DIDRange_DIDs_0100h_0110h/DCM_E_PENDING, DataServices_DIDRange_DIDs_0100h_0110h/E_NOT_OK]
        5 x arg:
          DID: type=uint16, direction=IN
          Data: type=DcmDspDidRangeArrayType_DIDs_0100h_0110h, direction=IN
          OpStatus: type=Dcm_OpStatusType, direction=IN
          DataLength: type=uint16, direction=IN
          ErrorCode: type=Dcm_NegativeResponseCodeType, direction=OUT
      operation IsDidAvailable: possible-error=[DataServices_DIDRange_DIDs_0100h_0110h/E_NOT_OK, DataServices_DIDRange_DIDs_0100h_0110h/DCM_E_PENDING]
        arg DID: type=uint16, direction=IN
        arg supported: type=uint8, direction=OUT
      error E_NOT_OK: error-code=1
      error DCM_E_PENDING: error-code=10
    SecurityAccess_L9
      operation CompareKey: possible-error=[SecurityAccess_L9/DCM_E_COMPARE_KEY_FAILED, SecurityAccess_L9/E_NOT_OK, SecurityAccess_L9/DCM_E_PENDING]
        arg Key: type=KeyArrayType_L9, direction=IN
        arg OpStatus: type=Dcm_OpStatusType, direction=IN
      operation GetSeed: possible-error=[SecurityAccess_L9/DCM_E_PENDING, SecurityAccess_L9/E_NOT_OK]
        arg OpStatus: type=Dcm_OpStatusType, direction=IN
        arg Seed: type=SeedArrayType_L9, direction=OUT
        arg ErrorCode: type=Dcm_NegativeResponseCodeType, direction=OUT
      error DCM_E_PENDING: error-code=10
      error DCM_E_COMPARE_KEY_FAILED: error-code=11
      error E_NOT_OK: error-code=1
    RoutineServices_RID_B194h_HSMConfigLockSecureDebug
      operation Start: possible-error=[RoutineServices_RID_B194h_HSMConfigLockSecureDebug/DCM_E_FORCE_RCRRP, RoutineServices_RID_B194h_HSMConfigLockSecureDebug/E_NOT_OK, RoutineServices_RID_B194h_HSMConfigLockSecureDebug/DCM_E_PENDING]
        4 x arg:
          OpStatus: type=Dcm_OpStatusType, direction=IN
          DataOut_B194h_StartRoutineOutSignal: type=StartFlexibleOutArrayDataType_RID_B194h_HSMConfigLockSecureDebug_B194h_StartRoutineOutSignal, direction=OUT
          currentDataLength: type=uint16, direction=INOUT
          ErrorCode: type=Dcm_NegativeResponseCodeType, direction=OUT
      error DCM_E_FORCE_RCRRP: error-code=12
      error E_NOT_OK: error-code=1
      error DCM_E_PENDING: error-code=10
package /AUTOSAR_Dcm/ServiceSwComponentTypes
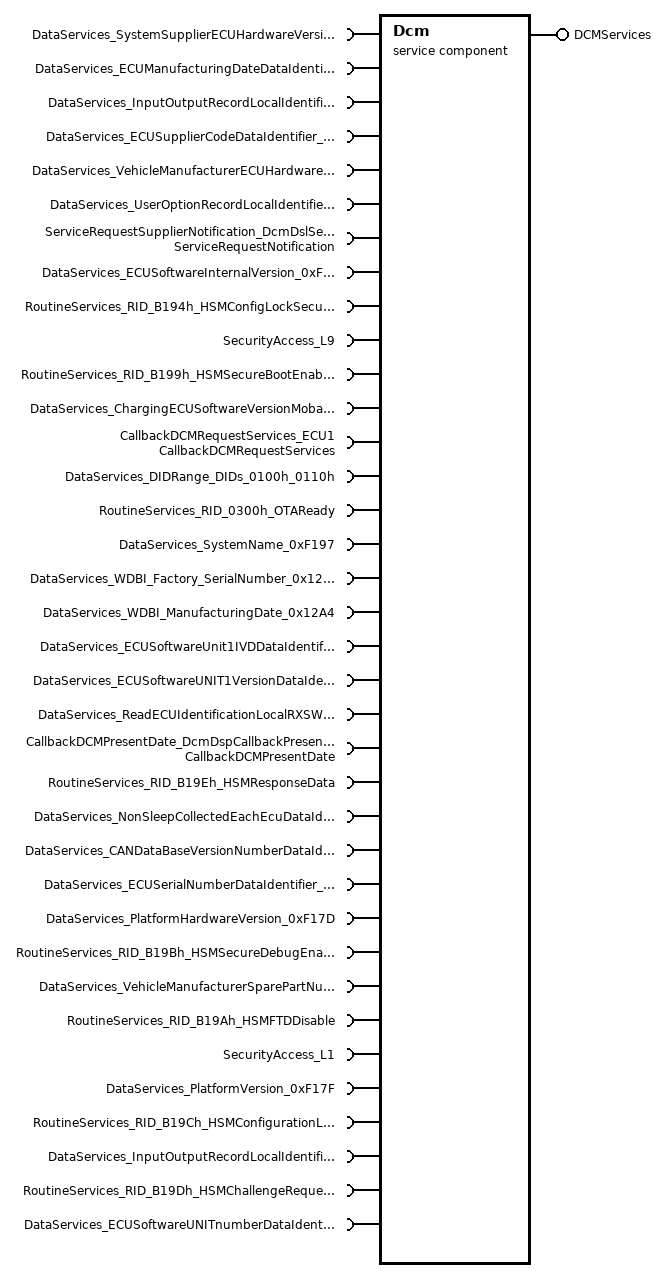
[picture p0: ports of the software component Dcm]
  service sw component type Dcm
    provide port DCMServices: provided-interface=DCMServices
      provided-com-specs:
        operation=ResetToDefaultSession, queue-length=1
        operation=GetActiveProtocol, queue-length=1
        operation=GetSecurityLevel, queue-length=1
        operation=GetSesCtrlType, queue-length=1
        operation=GetCertificationInfo, queue-length=1
    36 x require port:
      DataServices_SystemSupplierECUHardwareVersionNumberDataIdentifier_0xF193: required-interface=DataServices_SystemSupplierECUHardwareVersionNumberDataIdentifier_0xF193
        required-com-specs:
          DataServices_SystemSupplierECUHardwareVersionNumberDataIdentifier_0xF193/ReadData
          DataServices_SystemSupplierECUHardwareVersionNumberDataIdentifier_0xF193/ConditionCheckRead
      DataServices_ECUManufacturingDateDataIdentifier_0xF18B: required-interface=DataServices_ECUManufacturingDateDataIdentifier_0xF18B
        required-com-specs:
          DataServices_ECUManufacturingDateDataIdentifier_0xF18B/ReadData
          DataServices_ECUManufacturingDateDataIdentifier_0xF18B/ConditionCheckRead
      DataServices_InputOutputRecordLocalIdentifier_0xBE02: required-interface=DataServices_InputOutputRecordLocalIdentifier_0xBE02
        required-com-specs:
          DataServices_InputOutputRecordLocalIdentifier_0xBE02/ConditionCheckRead
          DataServices_InputOutputRecordLocalIdentifier_0xBE02/ReadData
      DataServices_ECUSupplierCodeDataIdentifier_0xF1A1: required-interface=DataServices_ECUSupplierCodeDataIdentifier_0xF1A1
        required-com-specs:
          DataServices_ECUSupplierCodeDataIdentifier_0xF1A1/ConditionCheckRead
          DataServices_ECUSupplierCodeDataIdentifier_0xF1A1/ReadData
      DataServices_VehicleManufacturerECUHardwareNumberDataIdentifier_0xF191: required-interface=DataServices_VehicleManufacturerECUHardwareNumberDataIdentifier_0xF191
        required-com-specs:
          DataServices_VehicleManufacturerECUHardwareNumberDataIdentifier_0xF191/ConditionCheckRead
          DataServices_VehicleManufacturerECUHardwareNumberDataIdentifier_0xF191/ReadData
      DataServices_UserOptionRecordLocalIdentifier_0xBE01: required-interface=DataServices_UserOptionRecordLocalIdentifier_0xBE01
        required-com-specs:
          DataServices_UserOptionRecordLocalIdentifier_0xBE01/ConditionCheckRead
          DataServices_UserOptionRecordLocalIdentifier_0xBE01/ReadData
      ServiceRequestSupplierNotification_DcmDslServiceRequestSupplierNotification0: required-com-specs=[Confirmation, Indication], required-interface=ServiceRequestNotification
      DataServices_ECUSoftwareInternalVersion_0xF189: required-interface=DataServices_ECUSoftwareInternalVersion_0xF189
        required-com-specs:
          DataServices_ECUSoftwareInternalVersion_0xF189/ConditionCheckRead
          DataServices_ECUSoftwareInternalVersion_0xF189/ReadData
      RoutineServices_RID_B194h_HSMConfigLockSecureDebug: client-com-spec=RoutineServices_RID_B194h_HSMConfigLockSecureDebug/Start, required-interface=RoutineServices_RID_B194h_HSMConfigLockSecureDebug
      SecurityAccess_L9: required-com-specs=[SecurityAccess_L9/CompareKey, SecurityAccess_L9/GetSeed], required-interface=SecurityAccess_L9
      RoutineServices_RID_B199h_HSMSecureBootEnable: client-com-spec=RoutineServices_RID_B199h_HSMSecureBootEnable/Start, required-interface=RoutineServices_RID_B199h_HSMSecureBootEnable
      DataServices_ChargingECUSoftwareVersionMobase_0xF101: required-interface=DataServices_ChargingECUSoftwareVersionMobase_0xF101
        required-com-specs:
          DataServices_ChargingECUSoftwareVersionMobase_0xF101/ReadData
          DataServices_ChargingECUSoftwareVersionMobase_0xF101/ConditionCheckRead
      CallbackDCMRequestServices_ECU1: required-com-specs=[StopProtocol, StartProtocol], required-interface=CallbackDCMRequestServices
      DataServices_DIDRange_DIDs_0100h_0110h: required-com-specs=[ReadDidData, WriteDidData, IsDidAvailable], required-interface=DataServices_DIDRange_DIDs_0100h_0110h
      RoutineServices_RID_0300h_OTAReady: client-com-spec=RoutineServices_RID_0300h_OTAReady/Start, required-interface=RoutineServices_RID_0300h_OTAReady
      DataServices_SystemName_0xF197: required-com-specs=[DataServices_SystemName_0xF197/ReadData, DataServices_SystemName_0xF197/ConditionCheckRead], required-interface=DataServices_SystemName_0xF197
      DataServices_WDBI_Factory_SerialNumber_0x12A3: client-com-spec=DataServices_WDBI_Factory_SerialNumber_0x12A3/WriteData, required-interface=DataServices_WDBI_Factory_SerialNumber_0x12A3
      DataServices_WDBI_ManufacturingDate_0x12A4: client-com-spec=DataServices_WDBI_ManufacturingDate_0x12A4/WriteData, required-interface=DataServices_WDBI_ManufacturingDate_0x12A4
      DataServices_ECUSoftwareUnit1IVDDataIdentifier_0xF1C1: required-interface=DataServices_ECUSoftwareUnit1IVDDataIdentifier_0xF1C1
        required-com-specs:
          DataServices_ECUSoftwareUnit1IVDDataIdentifier_0xF1C1/ConditionCheckRead
          DataServices_ECUSoftwareUnit1IVDDataIdentifier_0xF1C1/ReadData
      DataServices_ECUSoftwareUNIT1VersionDataIdentifier_0xF1B1: required-interface=DataServices_ECUSoftwareUNIT1VersionDataIdentifier_0xF1B1
        required-com-specs:
          DataServices_ECUSoftwareUNIT1VersionDataIdentifier_0xF1B1/ReadData
          DataServices_ECUSoftwareUNIT1VersionDataIdentifier_0xF1B1/ConditionCheckRead
      DataServices_ReadECUIdentificationLocalRXSWINDataIdentifier_0xF1EF: required-interface=DataServices_ReadECUIdentificationLocalRXSWINDataIdentifier_0xF1EF
        required-com-specs:
          DataServices_ReadECUIdentificationLocalRXSWINDataIdentifier_0xF1EF/ReadData
          DataServices_ReadECUIdentificationLocalRXSWINDataIdentifier_0xF1EF/ConditionCheckRead
      CallbackDCMPresentDate_DcmDspCallbackPresentDate: client-com-spec=GetPresentDate, required-interface=CallbackDCMPresentDate
      RoutineServices_RID_B19Eh_HSMResponseData: client-com-spec=RoutineServices_RID_B19Eh_HSMResponseData/Start, required-interface=RoutineServices_RID_B19Eh_HSMResponseData
      DataServices_NonSleepCollectedEachEcuDataIdentifier_0xED90: required-interface=DataServices_NonSleepCollectedEachEcuDataIdentifier_0xED90
        required-com-specs:
          DataServices_NonSleepCollectedEachEcuDataIdentifier_0xED90/ReadData
          DataServices_NonSleepCollectedEachEcuDataIdentifier_0xED90/ConditionCheckRead
      DataServices_CANDataBaseVersionNumberDataIdentifier_0xF100: required-interface=DataServices_CANDataBaseVersionNumberDataIdentifier_0xF100
        required-com-specs:
          DataServices_CANDataBaseVersionNumberDataIdentifier_0xF100/ReadData
          DataServices_CANDataBaseVersionNumberDataIdentifier_0xF100/ConditionCheckRead
      DataServices_ECUSerialNumberDataIdentifier_0xF18C: required-interface=DataServices_ECUSerialNumberDataIdentifier_0xF18C
        required-com-specs:
          DataServices_ECUSerialNumberDataIdentifier_0xF18C/ConditionCheckRead
          DataServices_ECUSerialNumberDataIdentifier_0xF18C/ReadData
      DataServices_PlatformHardwareVersion_0xF17D: required-interface=DataServices_PlatformHardwareVersion_0xF17D
        required-com-specs:
          DataServices_PlatformHardwareVersion_0xF17D/ReadData
          DataServices_PlatformHardwareVersion_0xF17D/ConditionCheckRead
      RoutineServices_RID_B19Bh_HSMSecureDebugEnable: client-com-spec=RoutineServices_RID_B19Bh_HSMSecureDebugEnable/Start, required-interface=RoutineServices_RID_B19Bh_HSMSecureDebugEnable
      DataServices_VehicleManufacturerSparePartNumberDataIdentifier_0xF187: required-interface=DataServices_VehicleManufacturerSparePartNumberDataIdentifier_0xF187
        required-com-specs:
          DataServices_VehicleManufacturerSparePartNumberDataIdentifier_0xF187/ReadData
          DataServices_VehicleManufacturerSparePartNumberDataIdentifier_0xF187/ConditionCheckRead
      RoutineServices_RID_B19Ah_HSMFTDDisable: client-com-spec=RoutineServices_RID_B19Ah_HSMFTDDisable/Start, required-interface=RoutineServices_RID_B19Ah_HSMFTDDisable
      SecurityAccess_L1: required-com-specs=[SecurityAccess_L1/CompareKey, SecurityAccess_L1/GetSeed], required-interface=SecurityAccess_L1
      DataServices_PlatformVersion_0xF17F: required-com-specs=[DataServices_PlatformVersion_0xF17F/ConditionCheckRead, DataServices_PlatformVersion_0xF17F/ReadData], required-interface=DataServices_PlatformVersion_0xF17F
      RoutineServices_RID_B19Ch_HSMConfigurationLockEnable: client-com-spec=RoutineServices_RID_B19Ch_HSMConfigurationLockEnable/Start, required-interface=RoutineServices_RID_B19Ch_HSMConfigurationLockEnable
      DataServices_InputOutputRecordLocalIdentifier_0xBE03: required-interface=DataServices_InputOutputRecordLocalIdentifier_0xBE03
        required-com-specs:
          DataServices_InputOutputRecordLocalIdentifier_0xBE03/ConditionCheckRead
          DataServices_InputOutputRecordLocalIdentifier_0xBE03/ReadData
      RoutineServices_RID_B19Dh_HSMChallengeRequest: client-com-spec=RoutineServices_RID_B19Dh_HSMChallengeRequest/Start, required-interface=RoutineServices_RID_B19Dh_HSMChallengeRequest
      DataServices_ECUSoftwareUNITnumberDataIdentifier_0xF1B0: required-interface=DataServices_ECUSoftwareUNITnumberDataIdentifier_0xF1B0
        required-com-specs:
          DataServices_ECUSoftwareUNITnumberDataIdentifier_0xF1B0/ReadData
          DataServices_ECUSoftwareUNITnumberDataIdentifier_0xF1B0/ConditionCheckRead
    behavior DcmInternalBehavior: handle-termination-and-restart=NO-SUPPORT, included-data-type-set=data-type=[Dcm_CertAuthorizationInfoType, DataArrayType_WDBI_Factory_SerialNumber_0x12A3, Dcm_OpStatusType, RequestDataArray, DataArrayType_ECUSupplierCodeDataIdentifier_0xF1A1, StartDataOutType_RID_B19Ch_HSMConfigurationLockEnable_B19Ch_StartRoutineOutSignal_ErrorCode, DataArrayType_VehicleManufacturerECUHardwareNumberDataIdentifier_0xF191, DataArrayType_SystemName_0xF197, DataArrayType_ECUSoftwareInternalVersion_0xF189, SeedArrayType_L1, Dcm_ConfirmationStatusType, StartDataOutType_RID_0300h_OTAReady_Out_RoutineStatus, KeyArrayType_L9, DataArrayType_ECUSoftwareUNIT1VersionDataIdentifier_0xF1B1, DataArrayType_SystemSupplierECUHardwareVersionNumberDataIdentifier_0xF193, DataArrayType_WDBI_ManufacturingDate_0x12A4, StartDataOutType_RID_B19Ch_HSMConfigurationLockEnable_B19Ch_StartRoutineOutSignal_State, StartDataOutType_RID_B199h_HSMSecureBootEnable_B199h_StartRoutineOutSignal_ErrorCode, DataArrayType_InputOutputRecordLocalIdentifier_0xBE02, Dcm_ProgConditionsType, Dcm_CertExpirationDateInfoType, Dcm_PresentDateType, DataArrayType_InputOutputRecordLocalIdentifier_0xBE03, Dcm_StatusType, StartDataOutType_RID_B19Ch_HSMConfigurationLockEnable_B19Ch_StartRoutineOutSignal_ReturnType, StartDataOutType_RID_B19Bh_HSMSecureDebugEnable_B19Bh_StartRoutineOutSignal_ErrorCode, DataArrayType_PlatformHardwareVersion_0xF17D, Dcm_MsgItemType, Dcm_IdContextType, StartFlexibleInArrayDataType_RID_B19Eh_HSMResponseData_B19Eh_StartRoutineInSignal_Data, DataArrayType_ECUSerialNumberDataIdentifier_0xF18C, DcmDspDidRangeArrayType_DIDs_0100h_0110h, DataArrayType_ECUSoftwareUNITnumberDataIdentifier_0xF1B0, DataArrayType_ECUSoftwareUnit1IVDDataIdentifier_0xF1C1, DataArrayType_CANDataBaseVersionNumberDataIdentifier_0xF100, Dcm_CertInfoType, Dcm_ReturnReadMemoryType, StartFlexibleOutArrayDataType_RID_B19Dh_HSMChallengeRequest_B19Dh_StartRoutineOutSignal_Data, DTRStatusType, Dcm_MsgLenType, StartDataOutType_RID_B19Bh_HSMSecureDebugEnable_B19Bh_StartRoutineOutSignal_State, SeedArrayType_L9, DataArrayType_PlatformVersion_0xF17F, KeyArrayType_L1, StartFlexibleOutArrayDataType_RID_B194h_HSMConfigLockSecureDebug_B194h_StartRoutineOutSignal, Dcm_SesCtrlType, DataArrayType_ReadECUIdentificationLocalRXSWINDataIdentifier_0xF1EF, Dcm_ReturnWriteMemoryType, Dcm_ProtocolType, StartDataOutType_RID_B19Bh_HSMSecureDebugEnable_B19Bh_StartRoutineOutSignal_ReturnType, Dcm_RoeStateType, DataArrayType_VehicleManufacturerSparePartNumberDataIdentifier_0xF187, DataArrayType_NonSleepCollectedEachEcuDataIdentifier_0xED90, StartDataOutType_RID_B199h_HSMSecureBootEnable_B199h_StartRoutineOutSignal_ReturnType, DataArrayType_ECUManufacturingDateDataIdentifier_0xF18B, DataArrayType_UserOptionRecordLocalIdentifier_0xBE01, StartDataOutType_RID_B19Ah_HSMFTDDisable_B19Ah_StartRoutineOutSignal_ErrorCode, StartDataOutType_RID_B19Ah_HSMFTDDisable_B19Ah_StartRoutineOutSignal_ReturnType, Dcm_SecLevelType, Dcm_NegativeResponseCodeType, Dcm_CommunicationModeType, StartDataOutType_RID_B199h_HSMSecureBootEnable_B199h_StartRoutineOutSignal_State, DataArrayType_ChargingECUSoftwareVersionMobase_0xF101, StartDataOutType_RID_B19Ah_HSMFTDDisable_B19Ah_StartRoutineOutSignal_State, Dcm_EcuStartModeType]
      5 x operation invoked event:
        OIE_DCMServices_ResetToDefaultSession: start-on-event=ResetToDefaultSession, operation=DCMServices.ResetToDefaultSession
        OIE_DCMServices_GetActiveProtocol: start-on-event=GetActiveProtocol, operation=DCMServices.GetActiveProtocol
        OIE_DCMServices_GetSecurityLevel: start-on-event=GetSecurityLevel, operation=DCMServices.GetSecurityLevel
        OIE_DCMServices_GetSesCtrlType: start-on-event=GetSesCtrlType, operation=DCMServices.GetSesCtrlType
        OIE_DCMServices_GetCertificationInfo: start-on-event=GetCertificationInfo, operation=DCMServices.GetCertificationInfo
      6 x runnable:
        ResetToDefaultSession: can-be-invoked-concurrently=true, symbol=Dcm_ResetToDefaultSession
        GetActiveProtocol: can-be-invoked-concurrently=true, symbol=Dcm_GetActiveProtocol
        GetSecurityLevel: can-be-invoked-concurrently=true, symbol=Dcm_GetSecurityLevel
        GetSesCtrlType: can-be-invoked-concurrently=true, symbol=Dcm_GetSesCtrlType
        GetCertificationInfo: can-be-invoked-concurrently=true, symbol=Dcm_GetCertificationInfo
        MainFunction: symbol=Dcm_MainFunction
          62 x sync call, all with timeout=0:
            SSCP_DataServices_SystemSupplierECUHardwareVersionNumberDataIdentifier_0xF193_ReadData: operation=DataServices_SystemSupplierECUHardwareVersionNumberDataIdentifier_0xF193.ReadData
            SSCP_DataServices_SystemSupplierECUHardwareVersionNumberDataIdentifier_0xF193_ConditionCheckRead: operation=DataServices_SystemSupplierECUHardwareVersionNumberDataIdentifier_0xF193.ConditionCheckRead
            SSCP_DataServices_ECUManufacturingDateDataIdentifier_0xF18B_ReadData: operation=DataServices_ECUManufacturingDateDataIdentifier_0xF18B.ReadData
            SSCP_DataServices_ECUManufacturingDateDataIdentifier_0xF18B_ConditionCheckRead: operation=DataServices_ECUManufacturingDateDataIdentifier_0xF18B.ConditionCheckRead
            SSCP_DataServices_InputOutputRecordLocalIdentifier_0xBE02_ConditionCheckRead: operation=DataServices_InputOutputRecordLocalIdentifier_0xBE02.ConditionCheckRead
            SSCP_DataServices_InputOutputRecordLocalIdentifier_0xBE02_ReadData: operation=DataServices_InputOutputRecordLocalIdentifier_0xBE02.ReadData
            SSCP_DataServices_ECUSupplierCodeDataIdentifier_0xF1A1_ConditionCheckRead: operation=DataServices_ECUSupplierCodeDataIdentifier_0xF1A1.ConditionCheckRead
            SSCP_DataServices_ECUSupplierCodeDataIdentifier_0xF1A1_ReadData: operation=DataServices_ECUSupplierCodeDataIdentifier_0xF1A1.ReadData
            SSCP_DataServices_VehicleManufacturerECUHardwareNumberDataIdentifier_0xF191_ConditionCheckRead: operation=DataServices_VehicleManufacturerECUHardwareNumberDataIdentifier_0xF191.ConditionCheckRead
            SSCP_DataServices_VehicleManufacturerECUHardwareNumberDataIdentifier_0xF191_ReadData: operation=DataServices_VehicleManufacturerECUHardwareNumberDataIdentifier_0xF191.ReadData
            SSCP_DataServices_UserOptionRecordLocalIdentifier_0xBE01_ConditionCheckRead: operation=DataServices_UserOptionRecordLocalIdentifier_0xBE01.ConditionCheckRead
            SSCP_DataServices_UserOptionRecordLocalIdentifier_0xBE01_ReadData: operation=DataServices_UserOptionRecordLocalIdentifier_0xBE01.ReadData
            SSCP_ServiceRequestSupplierNotification_DcmDslServiceRequestSupplierNotification0_Confirmation: operation=ServiceRequestSupplierNotification_DcmDslServiceRequestSupplierNotification0.Confirmation
            SSCP_ServiceRequestSupplierNotification_DcmDslServiceRequestSupplierNotification0_Indication: operation=ServiceRequestSupplierNotification_DcmDslServiceRequestSupplierNotification0.Indication
            SSCP_DataServices_ECUSoftwareInternalVersion_0xF189_ConditionCheckRead: operation=DataServices_ECUSoftwareInternalVersion_0xF189.ConditionCheckRead
            SSCP_DataServices_ECUSoftwareInternalVersion_0xF189_ReadData: operation=DataServices_ECUSoftwareInternalVersion_0xF189.ReadData
            SSCP_RoutineServices_RID_B194h_HSMConfigLockSecureDebug_Start: operation=RoutineServices_RID_B194h_HSMConfigLockSecureDebug.Start
            SSCP_SecurityAccess_L9_CompareKey: operation=SecurityAccess_L9.CompareKey
            SSCP_SecurityAccess_L9_GetSeed: operation=SecurityAccess_L9.GetSeed
            SSCP_RoutineServices_RID_B199h_HSMSecureBootEnable_Start: operation=RoutineServices_RID_B199h_HSMSecureBootEnable.Start
            SSCP_DataServices_ChargingECUSoftwareVersionMobase_0xF101_ReadData: operation=DataServices_ChargingECUSoftwareVersionMobase_0xF101.ReadData
            SSCP_DataServices_ChargingECUSoftwareVersionMobase_0xF101_ConditionCheckRead: operation=DataServices_ChargingECUSoftwareVersionMobase_0xF101.ConditionCheckRead
            SSCP_CallbackDCMRequestServices_ECU1_StopProtocol: operation=CallbackDCMRequestServices_ECU1.StopProtocol
            SSCP_CallbackDCMRequestServices_ECU1_StartProtocol: operation=CallbackDCMRequestServices_ECU1.StartProtocol
            SSCP_DataServices_DIDRange_DIDs_0100h_0110h_ReadDidData: operation=DataServices_DIDRange_DIDs_0100h_0110h.ReadDidData
            SSCP_DataServices_DIDRange_DIDs_0100h_0110h_WriteDidData: operation=DataServices_DIDRange_DIDs_0100h_0110h.WriteDidData
            SSCP_DataServices_DIDRange_DIDs_0100h_0110h_IsDidAvailable: operation=DataServices_DIDRange_DIDs_0100h_0110h.IsDidAvailable
            SSCP_RoutineServices_RID_0300h_OTAReady_Start: operation=RoutineServices_RID_0300h_OTAReady.Start
            SSCP_DataServices_SystemName_0xF197_ReadData: operation=DataServices_SystemName_0xF197.ReadData
            SSCP_DataServices_SystemName_0xF197_ConditionCheckRead: operation=DataServices_SystemName_0xF197.ConditionCheckRead
            SSCP_DataServices_WDBI_Factory_SerialNumber_0x12A3_WriteData: operation=DataServices_WDBI_Factory_SerialNumber_0x12A3.WriteData
            SSCP_DataServices_WDBI_ManufacturingDate_0x12A4_WriteData: operation=DataServices_WDBI_ManufacturingDate_0x12A4.WriteData
            SSCP_DataServices_ECUSoftwareUnit1IVDDataIdentifier_0xF1C1_ConditionCheckRead: operation=DataServices_ECUSoftwareUnit1IVDDataIdentifier_0xF1C1.ConditionCheckRead
            SSCP_DataServices_ECUSoftwareUnit1IVDDataIdentifier_0xF1C1_ReadData: operation=DataServices_ECUSoftwareUnit1IVDDataIdentifier_0xF1C1.ReadData
            SSCP_DataServices_ECUSoftwareUNIT1VersionDataIdentifier_0xF1B1_ReadData: operation=DataServices_ECUSoftwareUNIT1VersionDataIdentifier_0xF1B1.ReadData
            SSCP_DataServices_ECUSoftwareUNIT1VersionDataIdentifier_0xF1B1_ConditionCheckRead: operation=DataServices_ECUSoftwareUNIT1VersionDataIdentifier_0xF1B1.ConditionCheckRead
            SSCP_DataServices_ReadECUIdentificationLocalRXSWINDataIdentifier_0xF1EF_ReadData: operation=DataServices_ReadECUIdentificationLocalRXSWINDataIdentifier_0xF1EF.ReadData
            SSCP_DataServices_ReadECUIdentificationLocalRXSWINDataIdentifier_0xF1EF_ConditionCheckRead: operation=DataServices_ReadECUIdentificationLocalRXSWINDataIdentifier_0xF1EF.ConditionCheckRead
            SSCP_CallbackDCMPresentDate_DcmDspCallbackPresentDate_GetPresentDate: operation=CallbackDCMPresentDate_DcmDspCallbackPresentDate.GetPresentDate
            SSCP_RoutineServices_RID_B19Eh_HSMResponseData_Start: operation=RoutineServices_RID_B19Eh_HSMResponseData.Start
            SSCP_DataServices_NonSleepCollectedEachEcuDataIdentifier_0xED90_ReadData: operation=DataServices_NonSleepCollectedEachEcuDataIdentifier_0xED90.ReadData
            SSCP_DataServices_NonSleepCollectedEachEcuDataIdentifier_0xED90_ConditionCheckRead: operation=DataServices_NonSleepCollectedEachEcuDataIdentifier_0xED90.ConditionCheckRead
            SSCP_DataServices_CANDataBaseVersionNumberDataIdentifier_0xF100_ReadData: operation=DataServices_CANDataBaseVersionNumberDataIdentifier_0xF100.ReadData
            SSCP_DataServices_CANDataBaseVersionNumberDataIdentifier_0xF100_ConditionCheckRead: operation=DataServices_CANDataBaseVersionNumberDataIdentifier_0xF100.ConditionCheckRead
            SSCP_DataServices_ECUSerialNumberDataIdentifier_0xF18C_ConditionCheckRead: operation=DataServices_ECUSerialNumberDataIdentifier_0xF18C.ConditionCheckRead
            SSCP_DataServices_ECUSerialNumberDataIdentifier_0xF18C_ReadData: operation=DataServices_ECUSerialNumberDataIdentifier_0xF18C.ReadData
            SSCP_DataServices_PlatformHardwareVersion_0xF17D_ReadData: operation=DataServices_PlatformHardwareVersion_0xF17D.ReadData
            SSCP_DataServices_PlatformHardwareVersion_0xF17D_ConditionCheckRead: operation=DataServices_PlatformHardwareVersion_0xF17D.ConditionCheckRead
            SSCP_RoutineServices_RID_B19Bh_HSMSecureDebugEnable_Start: operation=RoutineServices_RID_B19Bh_HSMSecureDebugEnable.Start
            SSCP_DataServices_VehicleManufacturerSparePartNumberDataIdentifier_0xF187_ReadData: operation=DataServices_VehicleManufacturerSparePartNumberDataIdentifier_0xF187.ReadData
            SSCP_DataServices_VehicleManufacturerSparePartNumberDataIdentifier_0xF187_ConditionCheckRead: operation=DataServices_VehicleManufacturerSparePartNumberDataIdentifier_0xF187.ConditionCheckRead
            SSCP_RoutineServices_RID_B19Ah_HSMFTDDisable_Start: operation=RoutineServices_RID_B19Ah_HSMFTDDisable.Start
            SSCP_SecurityAccess_L1_CompareKey: operation=SecurityAccess_L1.CompareKey
            SSCP_SecurityAccess_L1_GetSeed: operation=SecurityAccess_L1.GetSeed
            SSCP_DataServices_PlatformVersion_0xF17F_ConditionCheckRead: operation=DataServices_PlatformVersion_0xF17F.ConditionCheckRead
            SSCP_DataServices_PlatformVersion_0xF17F_ReadData: operation=DataServices_PlatformVersion_0xF17F.ReadData
            SSCP_RoutineServices_RID_B19Ch_HSMConfigurationLockEnable_Start: operation=RoutineServices_RID_B19Ch_HSMConfigurationLockEnable.Start
            SSCP_DataServices_InputOutputRecordLocalIdentifier_0xBE03_ConditionCheckRead: operation=DataServices_InputOutputRecordLocalIdentifier_0xBE03.ConditionCheckRead
            SSCP_DataServices_InputOutputRecordLocalIdentifier_0xBE03_ReadData: operation=DataServices_InputOutputRecordLocalIdentifier_0xBE03.ReadData
            SSCP_RoutineServices_RID_B19Dh_HSMChallengeRequest_Start: operation=RoutineServices_RID_B19Dh_HSMChallengeRequest.Start
            SSCP_DataServices_ECUSoftwareUNITnumberDataIdentifier_0xF1B0_ReadData: operation=DataServices_ECUSoftwareUNITnumberDataIdentifier_0xF1B0.ReadData
            SSCP_DataServices_ECUSoftwareUNITnumberDataIdentifier_0xF1B0_ConditionCheckRead: operation=DataServices_ECUSoftwareUNITnumberDataIdentifier_0xF1B0.ConditionCheckRead
  swc implementation Dcm_SwcImplementation: programming-language=C, sw-version=1.0.0.0, swc-bsw-mapping=SwcBswMapping_Dcm, vendor-id=0, behavior=DcmInternalBehavior
    code-descriptors:
      code CodeDescriptor: artifact-descriptors=autosar-engineering-object={short-label=Dcm_LibObjects, category=SWLIB, domain=AUTOSAR_DCM}
    resource consumption ResourceConsumption
  swc bsw mapping SwcBswMapping_Dcm: bsw-behavior=InternalBehavior_Dcm, swc-bsw-runnable-mapping{bsw-entity=BswSE_Dcm_MainFunction, swc-runnable=MainFunction}, swc-behavior=DcmInternalBehavior
